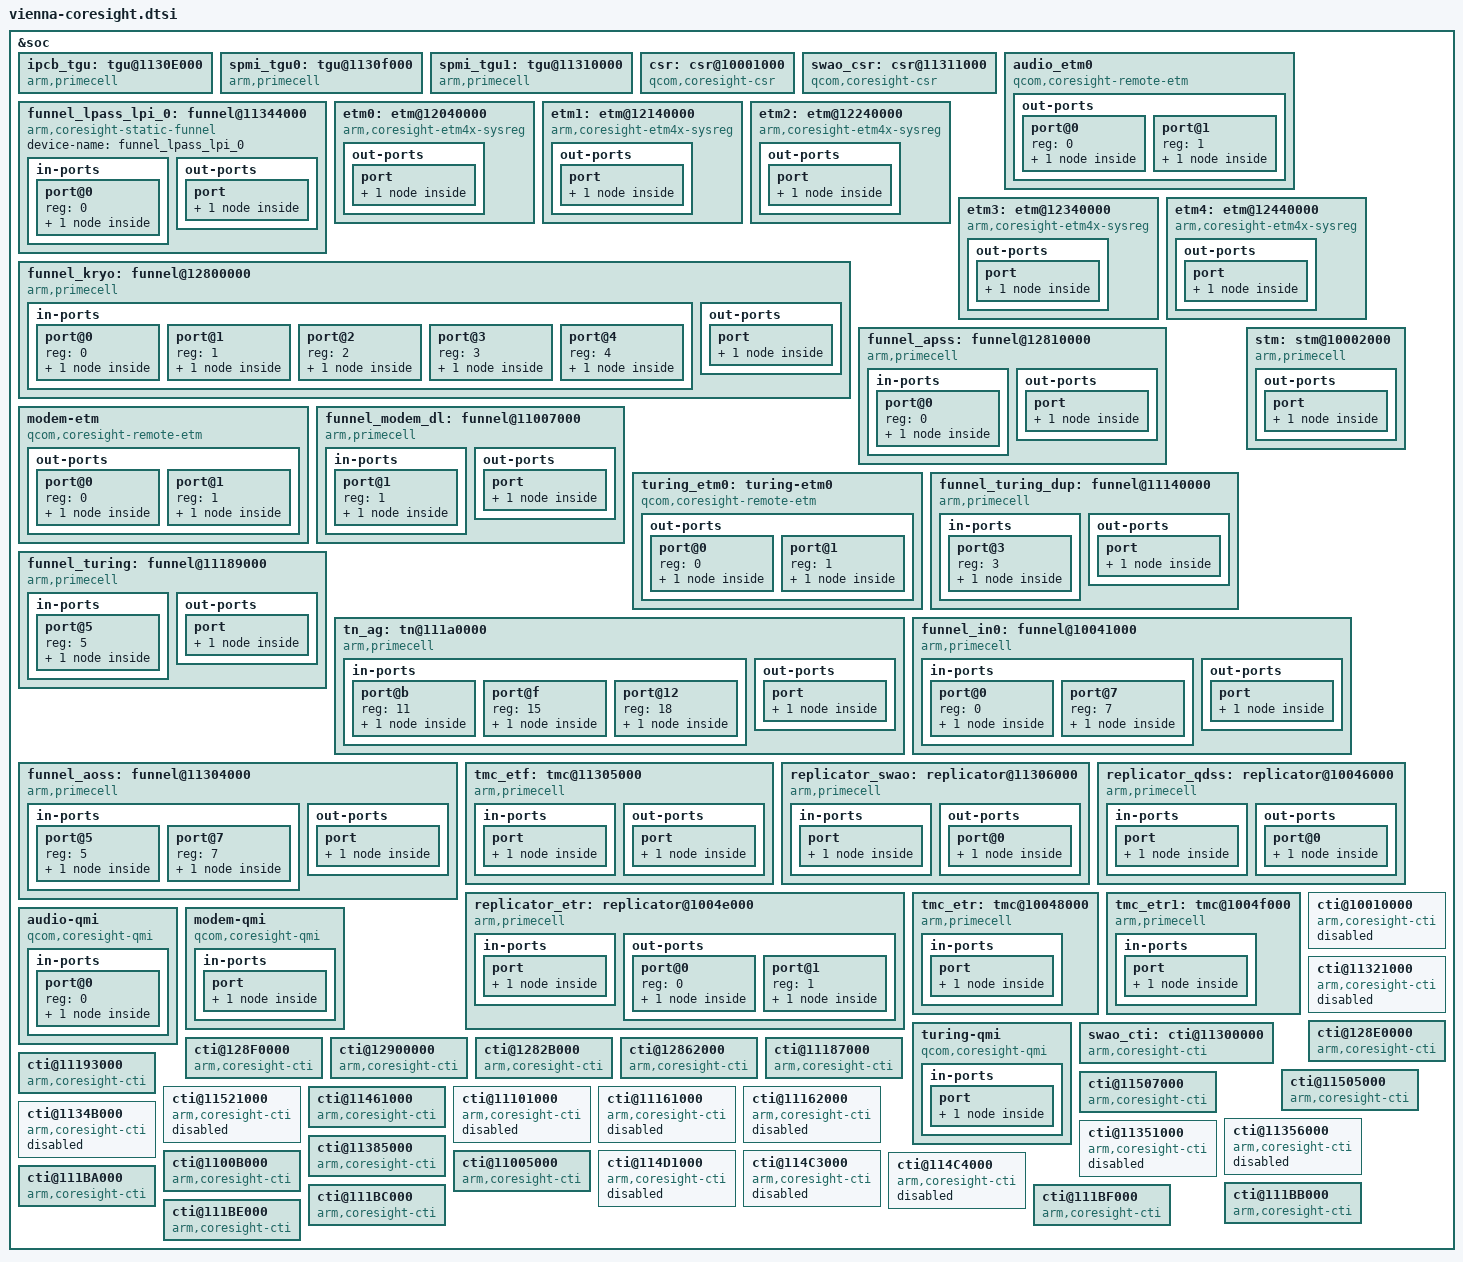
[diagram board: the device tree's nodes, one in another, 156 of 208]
// SPDX-License-Identifier: BSD-3-Clause
/*
 * Copyright (c) 2025 Qualcomm Innovation Center, Inc. All rights reserved.
 */

&soc {
	ipcb_tgu: tgu@1130E000 {
		compatible = "arm,primecell";
		arm,primecell-periphid = <0x000bb999>;
		reg = <0x1130E000 0x1000>;
		reg-names = "tgu-base";
		tgu-steps = <2>;
		tgu-conditions = <3>;
		tgu-regs = <4>;
		tgu-timer-counters = <2>;

		device-name = "tgu_ipcb";

		clocks = <&aoss_qmp>;
		clock-names = "apb_pclk";
	};

	spmi_tgu0: tgu@1130f000 {
		compatible = "arm,primecell";
		arm,primecell-periphid = <0x000bb999>;

		reg = <0x1130f000 0x1000>;
		reg-names = "tgu-base";

		tgu-steps = <2>;
		tgu-conditions = <3>;
		tgu-regs = <7>;
		tgu-timer-counters = <2>;

		device-name = "tgu_spmi0";

		clocks = <&aoss_qmp>;
		clock-names = "apb_pclk";
	};

	spmi_tgu1: tgu@11310000 {
		compatible = "arm,primecell";
		arm,primecell-periphid = <0x000bb999>;

		reg = <0x11310000 0x1000>;
		reg-names = "tgu-base";

		tgu-steps = <2>;
		tgu-conditions = <3>;
		tgu-regs = <7>;
		tgu-timer-counters = <2>;

		device-name = "tgu_spmi1";

		clocks = <&aoss_qmp>;
		clock-names = "apb_pclk";
	};

	csr: csr@10001000 {
		compatible = "qcom,coresight-csr";
		reg = <0x10001000 0x1000>;
		reg-names = "csr-base";

		device-name = "csr";

		qcom,hwctrl-set-support;
		qcom,set-byte-cntr-support;
		qcom,blk-size = <1>;
	};

	swao_csr: csr@11311000 {
		compatible = "qcom,coresight-csr";
		reg = <0x11311000 0x1000>,
		      <0x113110f8 0x78>;
		reg-names = "csr-base", "msr-base";

		device-name = "swao_csr";

		qcom,timestamp-support;
		qcom,msr-support;
		qcom,blk-size = <1>;

		clocks = <&aoss_qmp>;
		clock-names = "apb_pclk";
	};

	audio_etm0 {
		compatible = "qcom,coresight-remote-etm";

		device-name = "audio_etm0";
		qcom,atid-num = <2>;
		trace-name = "audio-etm0";
		atid = <40 41>;

		out-ports {
			port@0 {
				reg = <0>;
				audio_etm0_out_funnel_lpass_lpi: endpoint {
					remote-endpoint =
					<&funnel_lpass_lpi_in_audio_etm0>;
				};
			};

			port@1 {
				reg = <1>;
				audio_etm0_out_qmi: endpoint {
					remote-endpoint =
					<&qmi_in_audio_etm0>;
				};
			};
		};
	};

	funnel_lpass_lpi_0: funnel@11344000 {
		compatible = "arm,coresight-static-funnel";
		device-name = "funnel_lpass_lpi_0";

		in-ports {
			#address-cells = <1>;
			#size-cells = <0>;

			port@0 {
				reg = <0>;
				funnel_lpass_lpi_in_audio_etm0: endpoint {
					remote-endpoint =
					<&audio_etm0_out_funnel_lpass_lpi>;
				};
			};
		};

		out-ports {
			port {
				funnel_lpass_lpi_out_funnel_aoss: endpoint {
					remote-endpoint =
					<&funnel_aoss_in_funnel_lpass_lpi>;
				};
			};
		};
	};

	etm0: etm@12040000 {
		compatible = "arm,coresight-etm4x-sysreg";

		reg = <0x12040000 0x1000>;
		cpu = <&CPU0>;

		device-name = "etm0";

		qcom,skip-power-up;
		clocks = <&aoss_qmp>;
		clock-names = "apb_pclk";

		out-ports {
			port {
				etm0_out_funnel_kryo: endpoint {
				remote-endpoint = <&funnel_kryo_in_etm0>;
				};
			};
		};
	};

	etm1: etm@12140000 {
		compatible = "arm,coresight-etm4x-sysreg";

		reg = <0x12140000 0x1000>;
		cpu = <&CPU1>;

		device-name = "etm1";

		qcom,skip-power-up;
		clocks = <&aoss_qmp>;
		clock-names = "apb_pclk";

		out-ports {
			port {
				etm1_out_funnel_kryo: endpoint {
				remote-endpoint = <&funnel_kryo_in_etm1>;
				};
			};
		};
	};

	etm2: etm@12240000 {
		compatible = "arm,coresight-etm4x-sysreg";

		reg = <0x12240000 0x1000>;
		cpu = <&CPU2>;

		device-name = "etm2";

		qcom,skip-power-up;
		clocks = <&aoss_qmp>;
		clock-names = "apb_pclk";

		out-ports {
			port {
				etm2_out_funnel_kryo: endpoint {
				remote-endpoint = <&funnel_kryo_in_etm2>;
				};
			};
		};
	};

	etm3: etm@12340000 {
		compatible = "arm,coresight-etm4x-sysreg";

		reg = <0x12340000 0x1000>;
		cpu = <&CPU3>;

		device-name = "etm3";

		qcom,skip-power-up;
		clocks = <&aoss_qmp>;
		clock-names = "apb_pclk";

		out-ports {
			port {
				etm3_out_funnel_kryo: endpoint {
				remote-endpoint = <&funnel_kryo_in_etm3>;
				};
			};
		};
	};

	etm4: etm@12440000 {
		compatible = "arm,coresight-etm4x-sysreg";

		reg = <0x12440000 0x1000>;
		cpu = <&CPU4>;

		device-name = "etm4";

		qcom,skip-power-up;
		clocks = <&aoss_qmp>;
		clock-names = "apb_pclk";

		out-ports {
			port {
				etm4_out_funnel_kryo: endpoint {
				remote-endpoint = <&funnel_kryo_in_etm4>;
				};
			};
		};
	};

	funnel_kryo: funnel@12800000 {
		compatible = "arm,primecell";
		arm,primecell-periphid = <0x000bb908>;
		reg = <0x12800000 0x1000>;
		reg-names = "funnel-base";

		device-name = "funnel_kryo";

		clocks = <&aoss_qmp>;
		clock-names = "apb_pclk";

		in-ports {
			#address-cells = <1>;
			#size-cells = <0>;

			port@0 {
				reg = <0>;
				funnel_kryo_in_etm0: endpoint {
					remote-endpoint =
					<&etm0_out_funnel_kryo>;
				};
			};

			port@1 {
				reg = <1>;
				funnel_kryo_in_etm1: endpoint {
					remote-endpoint =
					<&etm1_out_funnel_kryo>;
				};
			};

			port@2 {
				reg = <2>;
				funnel_kryo_in_etm2: endpoint {
					remote-endpoint =
					<&etm2_out_funnel_kryo>;
				};
			};

			port@3 {
				reg = <3>;
				funnel_kryo_in_etm3: endpoint {
					remote-endpoint =
					<&etm3_out_funnel_kryo>;
				};
			};

			port@4 {
				reg = <4>;
				funnel_kryo_in_etm4: endpoint {
					remote-endpoint =
					<&etm4_out_funnel_kryo>;
				};
			};

		};

		out-ports {
			port {
				funnel_kryo_out_funnel_apss: endpoint {
					remote-endpoint =
					<&funnel_apss_in_funnel_kryo>;
				};
			};
		};
	};

	funnel_apss: funnel@12810000 {
		compatible = "arm,primecell";
		arm,primecell-periphid = <0x000bb908>;
		reg = <0x12810000 0x1000>;
		reg-names = "funnel-base";

		device-name = "funnel_apss";

		clocks = <&aoss_qmp>;
		clock-names = "apb_pclk";

		in-ports {
			#address-cells = <1>;
			#size-cells = <0>;

			port@0 {
				reg = <0>;
				funnel_apss_in_funnel_kryo: endpoint {
					remote-endpoint =
					<&funnel_kryo_out_funnel_apss>;
				};
			};
		};

		out-ports {
			port {
				funnel_apss_out_tn_ag: endpoint {
					remote-endpoint =
					<&tn_ag_in_funnel_apss>;
				};
			};
		};
	};

	modem-etm {
		compatible = "qcom,coresight-remote-etm";

		device-name = "modem_etm0";
		qcom,atid-num = <1>;
		atid = <36>;
		trace-name = "modem-etm";
		qcom,secure-component;

		out-ports {
			port@0 {
				reg = <0>;
				modem_etm_out_funnel_modem_dl: endpoint {
					remote-endpoint =
						<&funnel_modem_dl_in_modem_etm>;
				};
			};

			port@1 {
				reg = <1>;
				modem_etm_out_qmi: endpoint {
					remote-endpoint =
						<&qmi_in_modem_etm>;
				};
			};
		};
	};

	funnel_modem_dl: funnel@11007000 {
		compatible = "arm,primecell";
		arm,primecell-periphid = <0x000bb908>;
		reg = <0x11007000 0x1000>;
		reg-names = "funnel-base";

		device-name = "funnel_modem_dl";

		clocks = <&aoss_qmp>;
		clock-names = "apb_pclk";

		in-ports {

			#address-cells = <1>;
			#size-cells = <0>;

			port@1 {
				reg = <1>;
				funnel_modem_dl_in_modem_etm: endpoint {
					remote-endpoint =
					<&modem_etm_out_funnel_modem_dl>;
				};
			};
		};

		out-ports {
			port {
				funnel_modem_dl_out_tn_ag: endpoint {
					remote-endpoint =
					<&tn_ag_in_funnel_modem_dl>;
				};
			};
		};
	};

	turing_etm0: turing-etm0 {
		compatible = "qcom,coresight-remote-etm";

		device-name = "turing_etm0";

		qcom,atid-num = <2>;
		atid = <38 39>;
		trace-name = "turing-etm0";


		out-ports {
			port@0 {
				reg = <0>;
				turing_etm0_out_funnel_turing_dup: endpoint {
					remote-endpoint =
						<&funnel_turing_dup_in_turing_etm0>;
				};
			};

			port@1 {
				reg = <1>;
				turing_etm0_out_qmi: endpoint {
					remote-endpoint =
						<&qmi_in_turing_etm0>;
				};
			};
		};
	};

	funnel_turing_dup: funnel@11140000 {
		compatible = "arm,primecell";
		arm,primecell-periphid = <0x000bb908>;
		reg = <0x11140000 0x1000>,
			<0x11189000 0x1000>;
		reg-names = "funnel-base-dummy", "funnel-base-real";

		device-name = "funnel_turing_dup";

		qcom,duplicate-funnel;
		clocks = <&aoss_qmp>;
		clock-names = "apb_pclk";

		in-ports {
			#address-cells = <1>;
			#size-cells = <0>;
			port@3 {
				reg = <3>;
				funnel_turing_dup_in_turing_etm0: endpoint {
					remote-endpoint =
					<&turing_etm0_out_funnel_turing_dup>;
				};
			};
		};

		out-ports {
			port {
				funnel_turing_dup_out_funnel_turing: endpoint {
					remote-endpoint =
					<&funnel_turing_in_funnel_turing_dup>;
				};
			};
		};
	};

	funnel_turing: funnel@11189000 {
		compatible = "arm,primecell";
		arm,primecell-periphid = <0x000bb908>;
		reg = <0x11189000 0x1000>;
		reg-names = "funnel-base";

		device-name = "funnel_turing";

		clocks = <&aoss_qmp>;
		clock-names = "apb_pclk";

		in-ports {
			#address-cells = <1>;
			#size-cells = <0>;

			port@5 {
				reg = <5>;
				funnel_turing_in_funnel_turing_dup: endpoint {
					remote-endpoint =
					<&funnel_turing_dup_out_funnel_turing>;
				};
			};
		};

		out-ports {
			port {
				funnel_turing_out_tn_ag: endpoint {
					remote-endpoint =
					<&tn_ag_in_funnel_turing>;
				};
			};
		};
	};

	tn_ag: tn@111a0000 {
		compatible = "arm,primecell";
		arm,primecell-periphid = <0x000f0c00>;
		reg = <0x111a0000 0x3080>;
		reg-names = "traceNoc-base";

		device-name = "tracenoc_ag";

		clocks = <&aoss_qmp>;
		clock-names = "apb_pclk";
		qcom,trace-noc-v2;

		in-ports {
			#address-cells = <1>;
			#size-cells = <0>;

			port@b {
				reg = <11>;
				tn_ag_in_funnel_apss: endpoint {
					remote-endpoint =
					<&funnel_apss_out_tn_ag>;
				};
			};

			port@f {
				reg = <15>;
				tn_ag_in_funnel_modem_dl: endpoint {
					remote-endpoint =
					<&funnel_modem_dl_out_tn_ag>;
				};
			};

			port@12 {
				reg = <18>;
				tn_ag_in_funnel_turing: endpoint {
					remote-endpoint =
					<&funnel_turing_out_tn_ag>;
				};
			};
		};

		out-ports {
			port {
				tn_ag_out_funnel_in0: endpoint {
					remote-endpoint =
					<&funnel_in0_in_tn_ag>;
				};
			};
		};
	};

	stm: stm@10002000 {
		compatible = "arm,primecell";
		arm,primecell-periphid = <0x000bb962>;
		reg = <0x10002000 0x1000>,
			<0x37280000 0x180000>;
		reg-names = "stm-base", "stm-stimulus-base";

		device-name = "stm";
		atid = <16>;

		clocks = <&aoss_qmp>;
		clock-names = "apb_pclk";

		out-ports {
			port {
				stm_out_funnel_in0: endpoint {
					remote-endpoint =
					<&funnel_in0_in_stm>;
				};
			};
		};
	};

	funnel_in0: funnel@10041000 {
		compatible = "arm,primecell";
		arm,primecell-periphid = <0x000bb908>;
		reg = <0x10041000 0x1000>;
		reg-names = "funnel-base";

		device-name = "funnel_in0";

		clocks = <&aoss_qmp>;
		clock-names = "apb_pclk";

		in-ports {
			#address-cells = <1>;
			#size-cells = <0>;

			port@0 {
				reg = <0>;
				funnel_in0_in_tn_ag: endpoint {
					remote-endpoint =
					<&tn_ag_out_funnel_in0>;
				};
			};

			port@7 {
				reg = <7>;
				funnel_in0_in_stm: endpoint {
					remote-endpoint =
					<&stm_out_funnel_in0>;
				};
			};
		};

		out-ports {
			port {
				funnel_in0_out_funnel_aoss: endpoint {
					remote-endpoint =
					<&funnel_aoss_in_funnel_in0>;
				};
			};
		};
	};

	funnel_aoss: funnel@11304000 {
		compatible = "arm,primecell";
		arm,primecell-periphid = <0x000bb908>;
		reg = <0x11304000 0x1000>;
		reg-names = "funnel-base";

		device-name = "funnel_aoss";

		clocks = <&aoss_qmp>;
		clock-names = "apb_pclk";

		in-ports {
			#address-cells = <1>;
			#size-cells = <0>;

			port@5 {
				reg = <5>;
				funnel_aoss_in_funnel_lpass_lpi: endpoint {
					remote-endpoint =
					<&funnel_lpass_lpi_out_funnel_aoss>;
				};
			};

			port@7 {
				reg = <7>;
				funnel_aoss_in_funnel_in0: endpoint {
					remote-endpoint =
					<&funnel_in0_out_funnel_aoss>;
				};
			};

		};

		out-ports {
			port {
				funnel_aoss_out_tmc_etf: endpoint {
					remote-endpoint =
					<&tmc_etf_in_funnel_aoss>;
				};
			};
		};
	};

	tmc_etf: tmc@11305000 {
		compatible = "arm,primecell";
		arm,primecell-periphid = <0x000bb961>;
		reg = <0x11305000 0x1000>;
		reg-names = "tmc-base";

		device-name = "tmc_etf";

		clocks = <&aoss_qmp>;
		clock-names = "apb_pclk";

		in-ports {
			port {
				tmc_etf_in_funnel_aoss: endpoint {
					remote-endpoint =
					<&funnel_aoss_out_tmc_etf>;
				};
			};
		};

		out-ports {
			port {
				tmc_etf_out_replicator_swao: endpoint {
					remote-endpoint =
					<&replicator_swao_in_tmc_etf>;
				};
			};
		};
	};

	replicator_swao: replicator@11306000 {
		compatible = "arm,primecell";
		arm,primecell-periphid = <0x000bb909>;
		reg = <0x11306000 0x1000>;
		reg-names = "replicator-base";

		device-name = "replicator_swao";

		qcom,replicator-loses-context;
		clocks = <&aoss_qmp>;
		clock-names = "apb_pclk";

		in-ports {
			port {
				replicator_swao_in_tmc_etf: endpoint {
					remote-endpoint =
					<&tmc_etf_out_replicator_swao>;
				};
			};
		};

		out-ports {
			#address-cells = <1>;
			#size-cells = <0>;

			port@0 {
				replicator_swao_out_replicator_qdss: endpoint {
					remote-endpoint =
					<&replicator_qdss_in_replicator_swao>;
				};
			};
		};
	};

	replicator_qdss: replicator@10046000 {
		compatible = "arm,primecell";
		arm,primecell-periphid = <0x000bb909>;
		reg = <0x10046000 0x1000>;
		reg-names = "replicator-base";

		device-name = "replicator_qdss";

		clocks = <&aoss_qmp>;
		clock-names = "apb_pclk";

		in-ports {
			port {
				replicator_qdss_in_replicator_swao: endpoint {
					remote-endpoint =
					<&replicator_swao_out_replicator_qdss>;
				};
			};
		};

		out-ports {
			#address-cells = <1>;
			#size-cells = <0>;

			port@0 {
				replicator_qdss_out_replicator_etr: endpoint {
					remote-endpoint =
					<&replicator_etr_in_replicator_qdss>;
				};
			};
		};
	};

	replicator_etr: replicator@1004e000 {
		compatible = "arm,primecell";
		arm,primecell-periphid = <0x000bb909>;
		reg = <0x1004e000 0x1000>;
		reg-names = "replicator-base";

		device-name = "replicator_etr";

		clocks = <&aoss_qmp>;
		clock-names = "apb_pclk";

		in-ports {
			port {
				replicator_etr_in_replicator_qdss: endpoint {
					remote-endpoint =
					<&replicator_qdss_out_replicator_etr>;
				};
			};
		};

		out-ports {
			#address-cells = <1>;
			#size-cells = <0>;

			port@0 {
				reg = <0>;
				replicator_etr_out_tmc_etr: endpoint {
					remote-endpoint =
					<&tmc_etr_in_replicator_etr>;
				};
			};

			port@1 {
				reg = <1>;
				replicator_etr_out_tmc_etr1: endpoint {
					remote-endpoint =
					<&tmc_etr1_in_replicator_etr>;
				};
			};
		};
	};

	tmc_etr: tmc@10048000 {
		compatible = "arm,primecell";
		arm,primecell-periphid = <0x000bb961>;
		reg = <0x10048000 0x1000>;
		reg-names = "tmc-base";

		device-name = "tmc_etr";

		qcom,iommu-dma = "bypass";
		iommus = <&apps_smmu 0x03e0 0x40>;
		dma-coherent;
		arm,scatter-gather;

		qcom,sw-usb;
		coresight-csr = <&csr>;
		csr-atid-offset = <0xf8>;
		csr-irqctrl-offset = <0x6c>;
		byte-cntr-name = "byte-cntr";
		byte-cntr-class-name = "coresight-tmc-etr-stream";
		interrupts = <GIC_SPI 313 IRQ_TYPE_EDGE_RISING>;
		interrupt-names = "byte-cntr-irq";

		clocks = <&aoss_qmp>;
		clock-names = "apb_pclk";

		in-ports {
			port {
				tmc_etr_in_replicator_etr: endpoint {
					remote-endpoint =
					<&replicator_etr_out_tmc_etr>;
				};
			};
		};
	};

	tmc_etr1: tmc@1004f000 {
		compatible = "arm,primecell";
		arm,primecell-periphid = <0x000bb961>;
		reg = <0x1004f000 0x1000>;
		reg-names = "tmc-base";

		device-name = "tmc_etr1";

		qcom,iommu-dma = "bypass";
		iommus = <&apps_smmu 0x03c0 0x0>;
		dma-coherent;
		arm,scatter-gather;

		qcom,sw-usb;
		coresight-csr = <&csr>;
		csr-atid-offset = <0x108>;
		csr-irqctrl-offset = <0x70>;
		byte-cntr-name = "byte-cntr1";
		byte-cntr-class-name = "coresight-tmc-etr1-stream";
		interrupts = <GIC_SPI 314 IRQ_TYPE_EDGE_RISING>;
		interrupt-names = "byte-cntr-irq";

		clocks = <&aoss_qmp>;
		clock-names = "apb_pclk";

		in-ports {
			port {
				tmc_etr1_in_replicator_etr: endpoint {
					remote-endpoint =
					<&replicator_etr_out_tmc_etr1>;
				};
			};
		};
	};

	audio-qmi {
		compatible = "qcom,coresight-qmi";

		device-name = "qmi_auido";
		qcom,inst-id = <5>;

		in-ports {
			port@0 {
				reg = <0>;
				qmi_in_audio_etm0: endpoint {
					remote-endpoint =
						<&audio_etm0_out_qmi>;
				};
			};
		};
	};

	modem-qmi {
		compatible = "qcom,coresight-qmi";

		device-name = "qmi_modem";
		qcom,inst-id = <2>;

		in-ports {
			port {
				qmi_in_modem_etm: endpoint {
					remote-endpoint =
						<&modem_etm_out_qmi>;
				};
			};
		};
	};

	turing-qmi {
		compatible = "qcom,coresight-qmi";

		device-name = "qmi_turing";
		qcom,inst-id = <13>;

		in-ports {
			port {
				qmi_in_turing_etm0: endpoint {
					remote-endpoint =
						<&turing_etm0_out_qmi>;
				};
			};
		};
	};

	cti@10010000 {
		compatible = "arm,coresight-cti", "arm,primecell";
		reg = <0x10010000 0x1000>;

		arm,primecell-periphid = <0x000bb922>;
		device-name = "cti_qdss";

		qcom,extended_cti;
		clocks = <&aoss_qmp>;
		clock-names = "apb_pclk";
		status = "disabled";

		qcom,cti-gpio-trigout = <16>;
		pinctrl-names = "cti-trigout-pctrl";
		//pinctrl-0 = <&trigout_a>;
	};

	swao_cti: cti@11300000 {
		compatible = "arm,coresight-cti", "arm,primecell";
		reg = <0x11300000 0x1000>;

		arm,primecell-periphid = <0x000bb922>;
		device-name = "cti_swao";
		qcom,extended_cti;
		clocks = <&aoss_qmp>;
		clock-names = "apb_pclk";
	};

	cti@11321000 {
		compatible = "arm,coresight-cti", "arm,primecell";
		reg = <0x11321000 0x1000>;

		arm,primecell-periphid = <0x000bb922>;
		device-name = "cti_aoss";

		clocks = <&aoss_qmp>;
		clock-names = "apb_pclk";
		status = "disabled";
	};

	cti@128E0000 {
		compatible = "arm,coresight-cti", "arm,primecell";
		reg = <0x128E0000 0x1000>;

		arm,primecell-periphid = <0x000bb922>;
		device-name = "cti_apss_cti0";

		clocks = <&aoss_qmp>;
		clock-names = "apb_pclk";
	};

	cti@128F0000 {
		compatible = "arm,coresight-cti", "arm,primecell";
		reg = <0x128F0000 0x1000>;

		arm,primecell-periphid = <0x000bb922>;
		device-name = "cti_apss_cti1";

		clocks = <&aoss_qmp>;
		clock-names = "apb_pclk";
	};

	cti@12900000 {
		compatible = "arm,coresight-cti", "arm,primecell";
		reg = <0x12900000 0x1000>;

		arm,primecell-periphid = <0x000bb922>;
		device-name = "cti_apss_cti2";

		clocks = <&aoss_qmp>;
		clock-names = "apb_pclk";
	};

	cti@1282B000 {
		compatible = "arm,coresight-cti", "arm,primecell";
		reg = <0x1282B000 0x1000>;

		arm,primecell-periphid = <0x000bb922>;
		device-name = "cti_apss_epss";

		clocks = <&aoss_qmp>;
		clock-names = "apb_pclk";
	};

	cti@12862000 {
		compatible = "arm,coresight-cti", "arm,primecell";
		reg = <0x12862000 0x1000>;

		arm,primecell-periphid = <0x000bb922>;
		device-name = "cti_apss_dl";

		qcom,extended_cti;

		clocks = <&aoss_qmp>;
		clock-names = "apb_pclk";
	};

	cti@11187000 {
		compatible = "arm,coresight-cti", "arm,primecell";
		reg = <0x11187000 0x1000>;

		arm,primecell-periphid = <0x000bb922>;
		device-name = "cti_turing";

		qcom,extended_cti;
		clocks = <&aoss_qmp>;
		clock-names = "apb_pclk";
	};

	cti@11193000 {
		compatible = "arm,coresight-cti", "arm,primecell";
		reg = <0x11193000 0x1000>;

		arm,primecell-periphid = <0x000bb922>;
		device-name = "cti_turing_qdsp";

		clocks = <&aoss_qmp>;
		clock-names = "apb_pclk";
	};

	cti@11505000 {
		compatible = "arm,coresight-cti", "arm,primecell";
		reg = <0x11505000 0x1000>;

		arm,primecell-periphid = <0x000bb922>;
		device-name = "cti_ddr_center";

		qcom,extended_cti;
		clocks = <&aoss_qmp>;
		clock-names = "apb_pclk";
	};

	cti@11507000 {
		compatible = "arm,coresight-cti", "arm,primecell";
		reg = <0x11507000 0x1000>;

		arm,primecell-periphid = <0x000bb922>;
		device-name = "cti_ddr_chhm02";

		qcom,extended_cti;
		clocks = <&aoss_qmp>;
		clock-names = "apb_pclk";
	};

	cti@11521000 {
		compatible = "arm,coresight-cti", "arm,primecell";
		reg = <0x11521000 0x1000>;

		arm,primecell-periphid = <0x000bb922>;
		device-name = "cti_ddr_shrm";

		clocks = <&aoss_qmp>;
		clock-names = "apb_pclk";
		status = "disabled";
	};

	cti@11461000 {
		compatible = "arm,coresight-cti", "arm,primecell";
		reg = <0x11461000 0x1000>;

		arm,primecell-periphid = <0x000bb922>;
		device-name = "cti_wdss";

		qcom,extended_cti;
		clocks = <&aoss_qmp>;
		clock-names = "apb_pclk";
	};

	cti@11101000 {
		compatible = "arm,coresight-cti", "arm,primecell";
		reg = <0x11101000 0x1000>;

		arm,primecell-periphid = <0x000bb922>;
		device-name = "cti_a6x_dragonlink";

		qcom,extended_cti;
		clocks = <&aoss_qmp>;
		clock-names = "apb_pclk";
		status = "disabled";
	};

	cti@11161000 {
		compatible = "arm,coresight-cti", "arm,primecell";
		reg = <0x11161000 0x1000>;

		arm,primecell-periphid = <0x000bb922>;
		device-name = "cti_a6x_isdb";

		clocks = <&aoss_qmp>;
		clock-names = "apb_pclk";
		status = "disabled";
	};

	cti@11162000 {
		compatible = "arm,coresight-cti", "arm,primecell";
		reg = <0x11162000 0x1000>;

		arm,primecell-periphid = <0x000bb922>;
		device-name = "cti_a6x_gpmu";

		clocks = <&aoss_qmp>;
		clock-names = "apb_pclk";
		status = "disabled";
	};

	cti@1134B000 {
		compatible = "arm,coresight-cti", "arm,primecell";
		reg = <0x1134B000 0x1000>;

		arm,primecell-periphid = <0x000bb922>;
		device-name = "cti_lpass_lpi_qdsp";

		clocks = <&aoss_qmp>;
		clock-names = "apb_pclk";
		status = "disabled";
	};

	cti@11356000 {
		compatible = "arm,coresight-cti", "arm,primecell";
		reg = <0x11356000 0x1000>;

		arm,primecell-periphid = <0x000bb922>;
		device-name = "cti_lpass_lpi_cti_1";

		qcom,extended_cti;
		clocks = <&aoss_qmp>;
		clock-names = "apb_pclk";
		status = "disabled";
	};

	cti@11351000 {
		compatible = "arm,coresight-cti", "arm,primecell";
		reg = <0x11351000 0x1000>;

		arm,primecell-periphid = <0x000bb922>;
		device-name = "cti_lpass_lpi_cti_3";

		clocks = <&aoss_qmp>;
		clock-names = "apb_pclk";
		status = "disabled";
	};

	cti@11385000 {
		compatible = "arm,coresight-cti", "arm,primecell";
		reg = <0x11385000 0x1000>;

		arm,primecell-periphid = <0x000bb922>;
		device-name = "cti_lpass";

		qcom,extended_cti;
		clocks = <&aoss_qmp>;
		clock-names = "apb_pclk";
	};

	cti@1100B000 {
		compatible = "arm,coresight-cti", "arm,primecell";
		reg = <0x1100B000 0x1000>;

		arm,primecell-periphid = <0x000bb922>;
		device-name = "cti_mss_qdsp6";

		clocks = <&aoss_qmp>;
		clock-names = "apb_pclk";
	};

	cti@11005000 {
		compatible = "arm,coresight-cti", "arm,primecell";
		reg = <0x11005000 0x1000>;

		arm,primecell-periphid = <0x000bb922>;
		device-name = "cti_mss";

		qcom,extended_cti;
		clocks = <&aoss_qmp>;
		clock-names = "apb_pclk";
	};

	cti@114D1000 {
		compatible = "arm,coresight-cti", "arm,primecell";
		reg = <0x114D1000 0x1000>;

		arm,primecell-periphid = <0x000bb922>;
		device-name = "cti_tmess_rvss";

		clocks = <&aoss_qmp>;
		clock-names = "apb_pclk";
		status = "disabled";
	};

	cti@114C3000 {
		compatible = "arm,coresight-cti", "arm,primecell";
		reg = <0x114C3000 0x1000>;

		arm,primecell-periphid = <0x000bb922>;
		device-name = "cti_tmess_dragonlink_cti0";

		clocks = <&aoss_qmp>;
		clock-names = "apb_pclk";
		qcom,extended_cti;
		status = "disabled";
	};

	cti@114C4000 {
		compatible = "arm,coresight-cti", "arm,primecell";
		reg = <0x114C4000 0x1000>;

		arm,primecell-periphid = <0x000bb922>;
		device-name = "cti_tmess_dragonlink_cti1";

		clocks = <&aoss_qmp>;
		clock-names = "apb_pclk";
		qcom,extended_cti;
		status = "disabled";
	};

	cti@111BA000 {
		compatible = "arm,coresight-cti", "arm,primecell";
		reg = <0x111BA000 0x1000>;

		arm,primecell-periphid = <0x000bb922>;
		device-name = "cti_trace_noc_center0";

		clocks = <&aoss_qmp>;
		clock-names = "apb_pclk";
		qcom,extended_cti;
	};

	cti@111BB000 {
		compatible = "arm,coresight-cti", "arm,primecell";
		reg = <0x111BB000 0x1000>;

		arm,primecell-periphid = <0x000bb922>;
		device-name = "cti_trace_noc_center1";

		clocks = <&aoss_qmp>;
		clock-names = "apb_pclk";
		qcom,extended_cti;
	};

	cti@111BC000 {
		compatible = "arm,coresight-cti", "arm,primecell";
		reg = <0x111BC000 0x1000>;

		arm,primecell-periphid = <0x000bb922>;
		device-name = "cti_trace_noc_lpass";

		clocks = <&aoss_qmp>;
		clock-names = "apb_pclk";
		qcom,extended_cti;
	};

	cti@111BF000 {
		compatible = "arm,coresight-cti", "arm,primecell";
		reg = <0x111BF000 0x1000>;

		arm,primecell-periphid = <0x000bb922>;
		device-name = "cti_trace_noc_mm";

		clocks = <&aoss_qmp>;
		clock-names = "apb_pclk";
		qcom,extended_cti;
	};

	cti@111BE000 {
		compatible = "arm,coresight-cti", "arm,primecell";
		reg = <0x111BE000 0x1000>;

		arm,primecell-periphid = <0x000bb922>;
		device-name = "cti_trace_noc_tme";

		clocks = <&aoss_qmp>;
		clock-names = "apb_pclk";
		qcom,extended_cti;
	};
};
